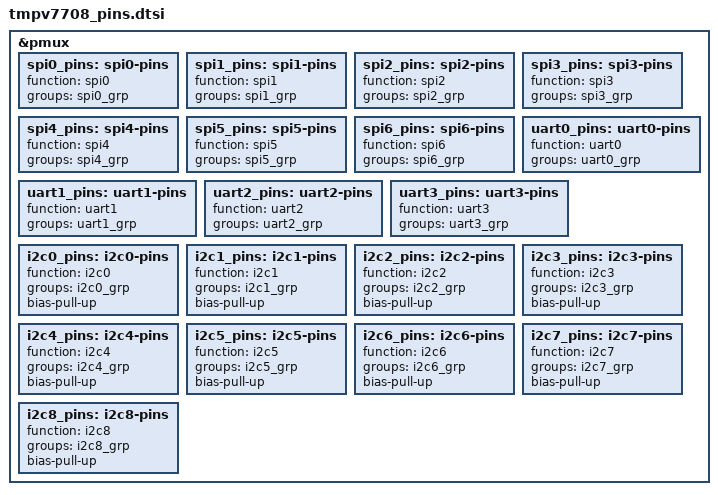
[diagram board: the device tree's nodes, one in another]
// SPDX-License-Identifier: (GPL-2.0+ OR MIT)

&pmux {
	spi0_pins: spi0-pins {
		function = "spi0";
		groups = "spi0_grp";
	};
	spi1_pins: spi1-pins {
		function = "spi1";
		groups = "spi1_grp";
	};
	spi2_pins: spi2-pins {
		function = "spi2";
		groups = "spi2_grp";
	};
	spi3_pins: spi3-pins {
		function = "spi3";
		groups = "spi3_grp";
	};
	spi4_pins: spi4-pins {
		function = "spi4";
		groups = "spi4_grp";
	};
	spi5_pins: spi5-pins {
		function = "spi5";
		groups = "spi5_grp";
	};
	spi6_pins: spi6-pins {
		function = "spi6";
		groups = "spi6_grp";
	};
	uart0_pins: uart0-pins {
		function = "uart0";
		groups = "uart0_grp";
	};
	uart1_pins: uart1-pins {
		function = "uart1";
		groups = "uart1_grp";
	};
	uart2_pins: uart2-pins {
		function = "uart2";
		groups = "uart2_grp";
	};
	uart3_pins: uart3-pins {
		function = "uart3";
		groups = "uart3_grp";
	};
	i2c0_pins: i2c0-pins {
		function = "i2c0";
		groups = "i2c0_grp";
		bias-pull-up;
	};
	i2c1_pins: i2c1-pins {
		function = "i2c1";
		groups = "i2c1_grp";
		bias-pull-up;
	};
	i2c2_pins: i2c2-pins {
		function = "i2c2";
		groups = "i2c2_grp";
		bias-pull-up;
	};
	i2c3_pins: i2c3-pins {
		function = "i2c3";
		groups = "i2c3_grp";
		bias-pull-up;
	};
	i2c4_pins: i2c4-pins {
		function = "i2c4";
		groups = "i2c4_grp";
		bias-pull-up;
	};
	i2c5_pins: i2c5-pins {
		function = "i2c5";
		groups = "i2c5_grp";
		bias-pull-up;
	};
	i2c6_pins: i2c6-pins {
		function = "i2c6";
		groups = "i2c6_grp";
		bias-pull-up;
	};
	i2c7_pins: i2c7-pins {
		function = "i2c7";
		groups = "i2c7_grp";
		bias-pull-up;
	};
	i2c8_pins: i2c8-pins {
		function = "i2c8";
		groups = "i2c8_grp";
		bias-pull-up;
	};
};
